VERSION ""

NS_ :

BS_:
BU_: ADC_sniffer
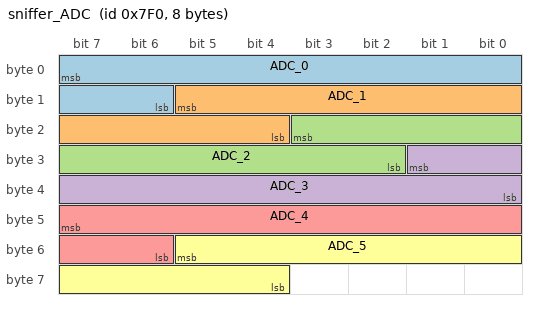
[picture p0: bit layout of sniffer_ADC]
BO_ 2032 sniffer_ADC: 8 ADC_sniffer
   SG_ ADC_0 : 7|10@0+ (1,0) [0|1] "" ADC_sniffer
   SG_ ADC_1 : 13|10@0+ (1,0) [0|1] "" ADC_sniffer
   SG_ ADC_2 : 19|10@0+ (1,0) [0|1] "" ADC_sniffer
   SG_ ADC_3 : 25|10@0+ (1,0) [0|1] "" ADC_sniffer
   SG_ ADC_4 : 47|10@0+ (1,0) [0|1] "" ADC_sniffer
   SG_ ADC_5 : 53|10@0+ (1,0) [0|1] "" ADC_sniffer

CM_ BU_ ADC_sniffer "Default node if none specified";
BA_DEF_ BO_ "GenMsgBackgroundColor" STRING ;
BA_DEF_ BO_ "GenMsgForegroundColor" STRING ;
BA_DEF_DEF_ "GenMsgBackgroundColor" "#ffffff";
BA_DEF_DEF_ "GenMsgForegroundColor" "#000000";
